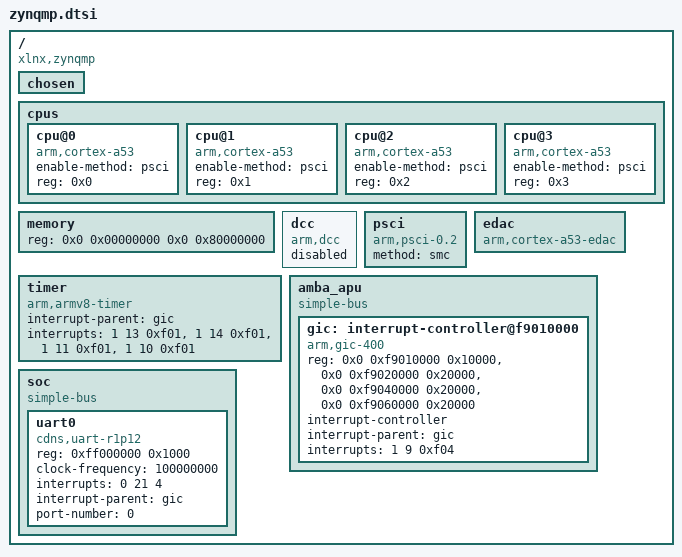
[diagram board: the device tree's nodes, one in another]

/ {
	compatible = "xlnx,zynqmp";
	#address-cells = <2>;
	#size-cells = <2>;

	chosen { };

	cpus {
		#address-cells = <1>;
		#size-cells = <0>;

		cpu@0 {
			compatible = "arm,cortex-a53", "arm,armv8";
			device_type = "cpu";
			enable-method = "psci";
			reg = <0x0>;
		};

		cpu@1 {
			compatible = "arm,cortex-a53", "arm,armv8";
			device_type = "cpu";
			enable-method = "psci";
			reg = <0x1>;
		};

		cpu@2 {
			compatible = "arm,cortex-a53", "arm,armv8";
			device_type = "cpu";
			enable-method = "psci";
			reg = <0x2>;
		};

		cpu@3 {
			compatible = "arm,cortex-a53", "arm,armv8";
			device_type = "cpu";
			enable-method = "psci";
			reg = <0x3>;
		};
	};

	memory {
		device_type = "memory";
		reg = <0x0 0x00000000 0x0 0x80000000>;
	};

	dcc: dcc {
		compatible = "arm,dcc";
		status = "disabled";
	};

	psci {
		compatible = "arm,psci-0.2";
		method = "smc";
	};

	timer {
		compatible = "arm,armv8-timer";
		interrupt-parent = <&gic>;
		interrupts = <1 13 0xf01>,
			     <1 14 0xf01>,
			     <1 11 0xf01>,
			     <1 10 0xf01>;
	};

	edac {
		compatible = "arm,cortex-a53-edac";
	};

	amba_apu: amba_apu {
		compatible = "simple-bus";
		#address-cells = <2>;
		#size-cells = <1>;

		gic: interrupt-controller@f9010000 {
			compatible = "arm,gic-400", "arm,cortex-a15-gic";
			#interrupt-cells = <3>;
			reg = <0x0 0xf9010000 0x10000>,
			      <0x0 0xf9020000 0x20000>,
			      <0x0 0xf9040000 0x20000>,
			      <0x0 0xf9060000 0x20000>;
			interrupt-controller;
			interrupt-parent = <&gic>;
			interrupts = <1 9 0xf04>;
		};
	};

	soc {
		compatible = "simple-bus";
		#address-cells = <1>;
		#size-cells = <1>;

		uart0: uart0 {
			compatible = "cdns,uart-r1p12", "xlnx,xuartps";
			reg = <0xff000000 0x1000>;
			clock-frequency = <100000000>;
			interrupts = <0 21 4>;
			interrupt-parent = <&gic>;
			device_type = "serial";
			port-number = <0>;
		};
	};
};
